VERSION ""

NS_ :

BS_:

BU_: BCM Vector__XX
VAL_TABLE_ MUWenabled 2 "MUW Master and Slave enabled" 1 "MUW Master only enabled" 0 "MUW not enabled" ;
VAL_TABLE_ VoltageState 2 "Critical Under Voltage State" 1 "Under Voltage State" 0 "Normal Voltage State" ;
VAL_TABLE_ Active 1 "Active" 0 "Not Active" ;
VAL_TABLE_ Open 1 "Open" 0 "Closed" ;
VAL_TABLE_ Fail 1 "Fail present" 0 "Fail not present" ;
VAL_TABLE_ Valid 1 "Not Valid" 0 "Valid" ;
VAL_TABLE_ ClutchPedalValidData 1 "Not Valid" 0 "Valid" ;
VAL_TABLE_ ClutchPedalAction 1 "Active" 0 "Not Active" ;
VAL_TABLE_ WakeUpReasons 58 "RB_LPMS_WKPR_NONE" 57 "RB_LPMS_WKPR_LPMS_FAILED" 56 "RB_LPMS_WKPR_MAX" 55 "RB_LPMS_WKPR_MUW_INCLINATION" 54 "RB_LPMS_WKPR_MUW_VOLUMETRIC" 53 "RB_LPMS_WKPR_LIN2_RX_NACK_ERR" 52 "RB_LPMS_WKPR_LIN2_RX_NAP_ERR" 51 "RB_LPMS_WKPR_LIN2_TX_ERR" 50 "RB_LPMS_WKPR_S_TASTER4" 49 "RB_LPMS_WKPR_S_TASTER3" 48 "RB_LPMS_WKPR_S_TASTER2" 47 "RB_LPMS_WKPR_S_TASTER1" 46 "RB_LPMS_WKPR_TAG_R" 45 "RB_LPMS_WKPR_TAG_L" 44 "RB_LPMS_WKPR_KL30G_FB" 43 "RB_LPMS_WKPR_LDS_RED" 42 "RB_LPMS_WKPR_IRUE_NGS_AUS" 41 "RB_LPMS_WKPR_HS_RASTE" 40 "RB_LPMS_WKPR_V_HR" 39 "RB_LPMS_WKPR_V_HL" 38 "RB_LPMS_WKPR_T_HDF" 37 "RB_LPMS_WKPR_SZ_HK" 36 "RB_LPMS_WKPR_LDS_ABL" 35 "RB_LPMS_WKPR_HK_HR" 34 "RB_LPMS_WKPR_HK_VR" 33 "RB_LPMS_WKPR_MOT_HAUBE2" 32 "RB_LPMS_WKPR_MOT_HAUBE1" 31 "RB_LPMS_WKPR_D_HR" 30 "RB_LPMS_WKPR_D_HL" 29 "RB_LPMS_WKPR_S_SOFTTOUCH" 28 "RB_LPMS_WKPR_L_U_TASTE" 27 "RB_LPMS_WKPR_LDS_SL" 26 "RB_LPMS_WKPR_S_WARNBLK" 25 "RB_LPMS_WKPR_KL15_ZAT2" 24 "RB_LPMS_WKPR_KL15_ZAT1" 23 "RB_LPMS_WKPR_KL15_ZAS2" 22 "RB_LPMS_WKPR_KL15_ZAS1" 21 "RB_LPMS_WKPR_KL_S_ZAS" 20 "RB_LPMS_WKPR_LIN14" 19 "RB_LPMS_WKPR_LIN13" 18 "RB_LPMS_WKPR_LIN12" 17 "RB_LPMS_WKPR_LIN11" 16 "RB_LPMS_WKPR_LIN10" 15 "RB_LPMS_WKPR_LIN9" 14 "RB_LPMS_WKPR_LIN8" 13 "RB_LPMS_WKPR_LIN7" 12 "RB_LPMS_WKPR_LIN6" 11 "RB_LPMS_WKPR_LIN5" 10 "RB_LPMS_WKPR_LIN4" 9 "RB_LPMS_WKPR_LIN3" 8 "RB_LPMS_WKPR_LIN2_SOUNDER_ALARM" 7 "RB_LPMS_WKPR_LIN2" 6 "RB_LPMS_WKPR_LIN1" 5 "RB_LPMS_WKPR_CAN3" 4 "RB_LPMS_WKPR_CAN2" 3 "RB_LPMS_WKPR_CAN1" 2 "RB_LPMS_WKPR_KESSY" 1 "RB_LPMS_WKPR_RF" 0 "RB_LPMS_WKPR_PWRON" ;
VAL_TABLE_ ResetReasons 255 "RB_LPMS__RESET_INIT" 254 "RB_LPMS__UNKNOWN_RESET" 47 "RB_LPMS_MST_ERROR_MBIST" 46 "RB_LPMS_MST_ERROR_UNDER_VOLTAGE" 45 "RB_LPMS_MST_ERROR_OVER_VOLTAGE" 44 "RB_LPMS_MST_ERROR_MONDMA" 43 "RB_LPMS_MST_ERROR_XBAR" 42 "RB_LPMS_MST_ERROR_REG_PROTECTION" 41 "RB_LPMS_MST_ERROR_BTST" 40 "RB_LPMS_MST_ERROR_CST" 39 "RB_LPMS_MST_ERROR_PFC" 38 "RB_LPMS_MST_ERROR_CRC" 37 "RB_LPMS_MST_ERROR_TESTMODE" 36 "RB_LPMS_MST_ERROR_STCU" 35 "RB_LPMS_MST_ERROR_DCF" 34 "RB_LPMS_KOT_BUS_ELAPSED" 33 "RB_LPMS_KOT_ECU_ELAPSED" 32 "RB_LPMS_SBC_LEAVING_FSP_MODE" 31 "RB_LPMS_SBC_ILLEGAL_SLEEP_MODE_COMMAND" 30 "RB_LPMS_SBC_V1_OUTPUT_VOLTAGE_ERROR" 29 "RB_LPMS_SBC_LEAVING_OVERLOAD_MODE" 28 "RB_LPMS_SBC_UC_SELF_RESET" 27 "RB_LPMS_SBC_WATCHDOG_ILLEGAL" 26 "RB_LPMS_SBC_WATCHDOG_OVERFLOW" 25 "RB_LPMS_SBC_WATCHDOG_EARLY" 24 "RB_LPMS_SBC_SLEEP_WATCHDOG_OVERFLOW" 23 "RB_LPMS_SBC_POWER_ON_RESET" 22 "RB_LPMS_FES_STDBY_VOLTAGE_ERROR" 21 "RB_LPMS_FES_VOLTAGE_ERROR" 20 "RB_LPMS_FES_TEMPERATURE_ERROR" 19 "RB_LPMS_FES_HSM_RESET" 18 "RB_LPMS_FES_JTAG_OR_STANDBY_EXIT" 17 "RB_LPMS_FES_FCCU_SOFT" 16 "RB_LPMS_FES_FCCU_HARD" 15 "RB_LPMS_FES_SW_RESET" 14 "RB_LPMS_FES_SELF_TEST_COMPLETED" 13 "RB_LPMS_FES_ESR1" 12 "RB_LPMS_DES_STDBY_VOLTAGE_ERROR" 11 "RB_LPMS_DES_VOLTAGE_ERROR" 10 "RB_LPMS_DES_TEMPERATURE_ERROR" 9 "RB_LPMS_DES_HSM_RESET" 8 "RB_LPMS_DES_HW_SSCM" 7 "RB_LPMS_DES_JTAG_RESET" 6 "RB_LPMS_DES_FLASH_FAILURE" 5 "RB_LPMS_DES_FUNCTIONAL" 4 "RB_LPMS_DES_HW_STCU" 3 "RB_LPMS_DES_HW_FCCU" 2 "RB_LPMS_DES_SW_RESET" 1 "RB_LPMS_DES_EXT_POR" 0 "RB_LPMS_MCU_POWER_ON_RESET" ;
VAL_TABLE_ ResetReason_Types 2 "RB_LPMS_MC_RGM_WAKEUP" 1 "RB_LPMS_MC_RGM_OTHER_RESET" 0 "RB_LPMS_MC_RGM_PWON_RESET" ;

BO_ 2665393424 DEBUG_10_SWInfo: 8 BCM
 SG_ DBG10_SwCounter : 39|32@0+ (10,0) [0|0] "ms" Vector__XXX
 SG_ DBG10_SWVersion : 7|32@0+ (1,0) [0|0] "" Vector__XXX

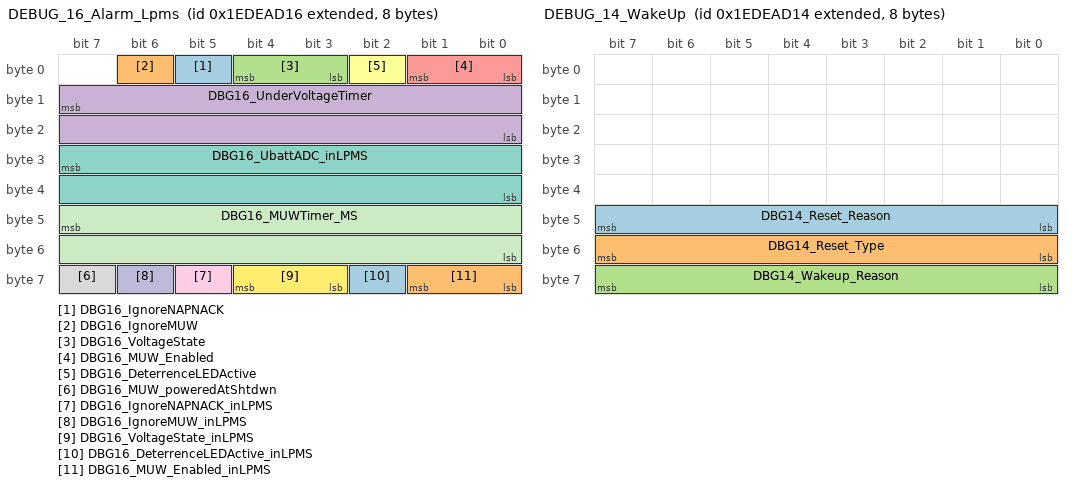
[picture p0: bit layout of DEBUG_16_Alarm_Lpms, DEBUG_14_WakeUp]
BO_ 2665393430 DEBUG_16_Alarm_Lpms: 8 BCM
 SG_ DBG16_IgnoreNAPNACK : 5|1@1+ (1,0) [0|0] "" Vector__XXX
 SG_ DBG16_IgnoreMUW : 6|1@1+ (1,0) [0|0] "" Vector__XXX
 SG_ DBG16_VoltageState : 3|2@1+ (1,0) [0|0] "" Vector__XXX
 SG_ DBG16_UnderVoltageTimer : 15|16@0+ (1,0) [0|0] "ms" Vector__XXX
 SG_ DBG16_MUW_Enabled : 0|2@1+ (1,0) [0|0] "" Vector__XXX
 SG_ DBG16_DeterrenceLEDActive : 2|1@1+ (1,0) [0|0] "" Vector__XXX
 SG_ DBG16_UbattADC_inLPMS : 31|16@0+ (0.000288600288600289,0) [0|18.9134199134199] "Volt" Vector__XXX
 SG_ DBG16_MUW_poweredAtShtdwn : 63|1@1+ (1,0) [0|0] "" Vector__XXX
 SG_ DBG16_IgnoreNAPNACK_inLPMS : 61|1@1+ (1,0) [0|0] "" Vector__XXX
 SG_ DBG16_IgnoreMUW_inLPMS : 62|1@1+ (1,0) [0|0] "" Vector__XXX
 SG_ DBG16_MUWTimer_MS : 47|16@0+ (1,0) [0|0] "ms" Vector__XXX
 SG_ DBG16_VoltageState_inLPMS : 59|2@1+ (1,0) [0|0] "" Vector__XXX
 SG_ DBG16_DeterrenceLEDActive_inLPMS : 58|1@1+ (1,0) [0|0] "" Vector__XXX
 SG_ DBG16_MUW_Enabled_inLPMS : 56|2@1+ (1,0) [0|0] "" Vector__XXX

BO_ 2665393428 DEBUG_14_WakeUp: 8 BCM
 SG_ DBG14_Reset_Reason : 40|8@1+ (1,0) [0|0] "" Vector__XXX
 SG_ DBG14_Reset_Type : 48|8@1+ (1,0) [0|0] "" Vector__XXX
 SG_ DBG14_Wakeup_Reason : 56|8@1+ (1,0) [0|0] "" Vector__XXX

BO_ 2665393429 DEBUG_15_Alarm_VF087: 8 BCM
 SG_ DBG15_PassengerPresence : 3|1@1+ (1,0) [0|1] "" Vector__XXX
 SG_ DBG15_DriverPresence : 2|1@1+ (1,0) [0|1] "" Vector__XXX
 SG_ DBG15_WAl_Activation : 1|1@1+ (1,0) [0|1] "" Vector__XXX
 SG_ DBG15_AlarmSupplySC : 0|8@0+ (1,0) [0|255] "" Vector__XXX
 SG_ DBG15_RFTrunk_VPSTrunkUnlckCntrl : 8|1@0+ (1,0) [0|1] "" Vector__XXX
 SG_ DBG15_TrunkExtCntrl : 23|1@0+ (1,0) [0|1] "" Vector__XXX
 SG_ DBG15_VPSBlinkUnlockCntrl : 22|1@0+ (1,0) [0|1] "" Vector__XXX
 SG_ DBG15_VPSBlinkLockCntrl : 21|1@0+ (1,0) [0|1] "" Vector__XXX
 SG_ DBG15_LIN2_ExtWakeup : 20|1@0+ (1,0) [0|1] "" Vector__XXX
 SG_ DBG15_MUWPowerSupply : 29|1@0+ (1,0) [0|1] "" Vector__XXX
 SG_ DBG15_SelfArmingCntrl : 28|1@0+ (1,0) [0|1] "" Vector__XXX
 SG_ DBG15_VPSAlarmONCntrl_NoMUW : 25|1@0+ (1,0) [0|1] "" Vector__XXX
 SG_ DBG15_VPSAlarmONCntrl : 24|1@0+ (1,0) [0|1] "" Vector__XXX
 SG_ DBG15_VPSAlarmOFFCntrl_NoMUW : 27|1@0+ (1,0) [0|1] "" Vector__XXX
 SG_ DBG15_VPSAlarmOFFCntrl : 26|1@0+ (1,0) [0|1] "" Vector__XXX
 SG_ DBG15_VPSAlarmModeCntrl : 16|3@0+ (1,0) [0|7] "" Vector__XXX
 SG_ DBG15_VPSAlarmBlinkCntrl : 19|3@0+ (1,0) [0|7] "" Vector__XXX
 SG_ DBG15_Excl_MUWStsNoMUW : 39|1@0+ (1,0) [0|1] "" Vector__XXX
 SG_ DBG15_MUWSignal : 38|1@0+ (1,0) [0|1] "" Vector__XXX
 SG_ DBG15_DeterringLed : 37|1@0+ (1,0) [0|1] "" Vector__XXX
 SG_ DBG15_VPSAlarmIFSts : 36|2@0+ (1,0) [0|1] "" Vector__XXX
 SG_ DBG15_VPSAlarmAntinclSts : 34|2@0+ (1,0) [0|1] "" Vector__XXX
 SG_ DBG15_UMAlarmCauseSts : 45|1@0+ (1,0) [0|1] "" Vector__XXX
 SG_ DBG15_AMAlarmCauseSts : 44|1@0+ (1,0) [0|1] "" Vector__XXX
 SG_ DBG15_BonnetAlarmCauseSts : 43|1@0+ (1,0) [0|1] "" Vector__XXX
 SG_ DBG15_RHatchAlarmCauseSts : 42|1@0+ (1,0) [0|1] "" Vector__XXX
 SG_ DBG15_DoorAlarmCausesSts : 41|1@0+ (1,0) [0|1] "" Vector__XXX
 SG_ DBG15_INTInfoAlarmCausesSts : 40|1@0+ (1,0) [0|1] "" Vector__XXX
 SG_ DBG15_Excl_MUWStsWAL : 51|1@0+ (1,0) [0|1] "" Vector__XXX
 SG_ DBG15_ASUAlarmCauseSts : 32|3@0+ (1,0) [0|7] "" Vector__XXX
 SG_ DBG15_StateOfAlarmSystem : 55|4@0+ (1,0) [0|15] "" Vector__XXX
 SG_ DBG15_Excl_PsngrDoorWAL : 50|1@0+ (1,0) [0|1] "" Vector__XXX
 SG_ DBG15_Excl_DriverDoorWAL : 49|1@0+ (1,0) [0|1] "" Vector__XXX
 SG_ DBG15_Excl_UMSts : 63|1@0+ (1,0) [0|1] "" Vector__XXX
 SG_ DBG15_Excl_ASUSts : 48|1@0+ (1,0) [0|1] "" Vector__XXX
 SG_ DBG15_Excl_AMSts : 62|1@0+ (1,0) [0|1] "" Vector__XXX
 SG_ DBG15_SBMT_VpsDoorUnlckCntrl_F08 : 60|1@0+ (1,0) [0|1] "" Vector__XXX
 SG_ DBG15_Excl_TrunkSts : 61|1@0+ (1,0) [0|1] "" Vector__XXX
 SG_ DBG15_SBMT_EnableGlovebox_VF008 : 58|1@0+ (1,0) [0|1] "" Vector__XXX
 SG_ DBG15_SBMT_EnbleDomeLckUnlck_F08 : 59|1@0+ (1,0) [0|1] "" Vector__XXX
 SG_ DBG15_SBMT_EnableDomeLight_VF008 : 57|1@0+ (1,0) [0|1] ""  Vector__XX

CM_ "C1-CAN Network

Created from Signal List file: CommonSignalList_C1-CAN_2021_03_18_Rev449.xls
With Message Map file: F175_MM_C1-CAN_2021_03_18_rev124.xls
for project: F175

Created on: 18/03/2021, 18:02:41
By automated tool: Genera_dbc 4.2.E
Launched by: FERRARI_IP\JMolinari
Ferrari - S.E.E.";
CM_ BU_ BCM "Nodo Body Computer";
BA_DEF_ SG_  "GenSigSendType" ENUM  "NotUsed","OnWrite","OnWriteWithRepetition","OnChange","OnChangeWithRepetition","IfActive","IfActiveWithRepetition","NoSigSendType";
BA_DEF_ BO_  "GenMsgSendType" ENUM  "Cyclic","NotUsed","NotUsed","NotUsed","NotUsed","NotUsed","NotUsed","NotUsed","NoMsgSendType";
BA_DEF_ BO_  "Type" ENUM  "P","C","PE","COC","PE_Cntrl","E","E_Cntrl","OC","S","BAF","DC","EM","MM","-";
BA_DEF_ BU_  "TpOwnSystemEcuNumber" HEX 0 255;
BA_DEF_ BU_  "NwmNodeType" ENUM  "kMaster","kSlave15","kSlave30","none";
BA_DEF_ BU_  "NmNodeType" ENUM  "kMaster","kSlave15","kSlave30","none";
BA_DEF_ BU_  "ILUsed" ENUM  "No","Yes";
BA_DEF_ BU_  "NmNode" ENUM  "No","Yes";
BA_DEF_ BU_  "NmStationAddress" HEX 0 255;
BA_DEF_ BU_  "NodeLayerModules" STRING ;
BA_DEF_ BU_  "Description" STRING ;
BA_DEF_ BU_  "NodeAddress" INT 0 127;
BA_DEF_  "Manufacturer" STRING ;
BA_DEF_  "VersionYear" INT 0 99;
BA_DEF_  "VersionWeek" INT 0 53;
BA_DEF_  "Version" HEX 0 255;
BA_DEF_  "DBName" STRING ;
BA_DEF_  "Baudrate" INT 0 1000000;
BA_DEF_  "NmType" STRING ;
BA_DEF_  "BusType" STRING ;
BA_DEF_DEF_  "GenSigSendType" "NoSigSendType";
BA_DEF_DEF_  "GenMsgSendType" "NoMsgSendType";
BA_DEF_DEF_  "Type" "-";
BA_DEF_DEF_  "TpOwnSystemEcuNumber" 0;
BA_DEF_DEF_  "NwmNodeType" "none";
BA_DEF_DEF_  "NmNodeType" "none";
BA_DEF_DEF_  "ILUsed" "Yes";
BA_DEF_DEF_  "NmNode" "Yes";
BA_DEF_DEF_  "NmStationAddress" 0;
BA_DEF_DEF_  "NodeLayerModules" "Osek_TP.dll";
BA_DEF_DEF_  "Description" "";
BA_DEF_DEF_  "NodeAddress" 0;
BA_DEF_DEF_  "Manufacturer" "Ferrari";
BA_DEF_DEF_  "VersionYear" 13;
BA_DEF_DEF_  "VersionWeek" 51;
BA_DEF_DEF_  "Version" 160;
BA_DEF_DEF_  "DBName" "CAN";
BA_DEF_DEF_  "Baudrate" 500000;
BA_DEF_DEF_  "NmType" "";
BA_DEF_DEF_  "BusType" "";
BA_ "BusType" "CAN";
BA_ "NmType" "Fiat_Class_C";
BA_ "Version" 124;
BA_ "VersionWeek" 11;
BA_ "VersionYear" 21;
BA_ "DBName" "C1CAN";
BA_ "Description" BU_ BCM "Nodo Body Computer";
BA_ "NmNodeType" BU_ BCM 0;
BA_ "NwmNodeType" BU_ BCM 0;
BA_ "TpOwnSystemEcuNumber" BU_ BCM 64;
BA_ "NmStationAddress" BU_ BCM 64;
VAL_ 2665393430 DBG16_VoltageState 2 "Critical Under Voltage State" 1 "Under Voltage State" 0 "Normal Voltage State" ;
VAL_ 2665393430 DBG16_MUW_Enabled 2 "MUW Master and Slave enabled" 1 "MUW Master only enabled" 0 "MUW not enabled" ;
VAL_ 2665393430 DBG16_VoltageState_inLPMS 2 "Critical Under Voltage State" 1 "Under Voltage State" 0 "Normal Voltage State" ;
VAL_ 2665393430 DBG16_MUW_Enabled_inLPMS 2 "MUW Master and Slave enabled" 1 "MUW Master only enabled" 0 "MUW not enabled" ;
VAL_ 2665393428 DBG14_Reset_Reason 255 "RB_LPMS__RESET_INIT" 254 "RB_LPMS__UNKNOWN_RESET" 47 "RB_LPMS_MST_ERROR_MBIST" 46 "RB_LPMS_MST_ERROR_UNDER_VOLTAGE" 45 "RB_LPMS_MST_ERROR_OVER_VOLTAGE" 44 "RB_LPMS_MST_ERROR_MONDMA" 43 "RB_LPMS_MST_ERROR_XBAR" 42 "RB_LPMS_MST_ERROR_REG_PROTECTION" 41 "RB_LPMS_MST_ERROR_BTST" 40 "RB_LPMS_MST_ERROR_CST" 39 "RB_LPMS_MST_ERROR_PFC" 38 "RB_LPMS_MST_ERROR_CRC" 37 "RB_LPMS_MST_ERROR_TESTMODE" 36 "RB_LPMS_MST_ERROR_STCU" 35 "RB_LPMS_MST_ERROR_DCF" 34 "RB_LPMS_KOT_BUS_ELAPSED" 33 "RB_LPMS_KOT_ECU_ELAPSED" 32 "RB_LPMS_SBC_LEAVING_FSP_MODE" 31 "RB_LPMS_SBC_ILLEGAL_SLEEP_MODE_COMMAND" 30 "RB_LPMS_SBC_V1_OUTPUT_VOLTAGE_ERROR" 29 "RB_LPMS_SBC_LEAVING_OVERLOAD_MODE" 28 "RB_LPMS_SBC_UC_SELF_RESET" 27 "RB_LPMS_SBC_WATCHDOG_ILLEGAL" 26 "RB_LPMS_SBC_WATCHDOG_OVERFLOW" 25 "RB_LPMS_SBC_WATCHDOG_EARLY" 24 "RB_LPMS_SBC_SLEEP_WATCHDOG_OVERFLOW" 23 "RB_LPMS_SBC_POWER_ON_RESET" 22 "RB_LPMS_FES_STDBY_VOLTAGE_ERROR" 21 "RB_LPMS_FES_VOLTAGE_ERROR" 20 "RB_LPMS_FES_TEMPERATURE_ERROR" 19 "RB_LPMS_FES_HSM_RESET" 18 "RB_LPMS_FES_JTAG_OR_STANDBY_EXIT" 17 "RB_LPMS_FES_FCCU_SOFT" 16 "RB_LPMS_FES_FCCU_HARD" 15 "RB_LPMS_FES_SW_RESET" 14 "RB_LPMS_FES_SELF_TEST_COMPLETED" 13 "RB_LPMS_FES_ESR1" 12 "RB_LPMS_DES_STDBY_VOLTAGE_ERROR" 11 "RB_LPMS_DES_VOLTAGE_ERROR" 10 "RB_LPMS_DES_TEMPERATURE_ERROR" 9 "RB_LPMS_DES_HSM_RESET" 8 "RB_LPMS_DES_HW_SSCM" 7 "RB_LPMS_DES_JTAG_RESET" 6 "RB_LPMS_DES_FLASH_FAILURE" 5 "RB_LPMS_DES_FUNCTIONAL" 4 "RB_LPMS_DES_HW_STCU" 3 "RB_LPMS_DES_HW_FCCU" 2 "RB_LPMS_DES_SW_RESET" 1 "RB_LPMS_DES_EXT_POR" 0 "RB_LPMS_MCU_POWER_ON_RESET" ;
VAL_ 2665393428 DBG14_Reset_Type 2 "RB_LPMS_MC_RGM_WAKEUP" 1 "RB_LPMS_MC_RGM_OTHER_RESET" 0 "RB_LPMS_MC_RGM_PWON_RESET" ;
VAL_ 2665393428 DBG14_Wakeup_Reason 58 "RB_LPMS_WKPR_NONE" 57 "RB_LPMS_WKPR_LPMS_FAILED" 56 "RB_LPMS_WKPR_MAX" 55 "RB_LPMS_WKPR_MUW_INCLINATION" 54 "RB_LPMS_WKPR_MUW_VOLUMETRIC" 53 "RB_LPMS_WKPR_LIN2_RX_NACK_ERR" 52 "RB_LPMS_WKPR_LIN2_RX_NAP_ERR" 51 "RB_LPMS_WKPR_LIN2_TX_ERR" 50 "RB_LPMS_WKPR_S_TASTER4" 49 "RB_LPMS_WKPR_S_TASTER3" 48 "RB_LPMS_WKPR_S_TASTER2" 47 "RB_LPMS_WKPR_S_TASTER1" 46 "RB_LPMS_WKPR_TAG_R" 45 "RB_LPMS_WKPR_TAG_L" 44 "RB_LPMS_WKPR_KL30G_FB" 43 "RB_LPMS_WKPR_LDS_RED" 42 "RB_LPMS_WKPR_IRUE_NGS_AUS" 41 "RB_LPMS_WKPR_HS_RASTE" 40 "RB_LPMS_WKPR_V_HR" 39 "RB_LPMS_WKPR_V_HL" 38 "RB_LPMS_WKPR_T_HDF" 37 "RB_LPMS_WKPR_SZ_HK" 36 "RB_LPMS_WKPR_LDS_ABL" 35 "RB_LPMS_WKPR_HK_HR" 34 "RB_LPMS_WKPR_HK_VR" 33 "RB_LPMS_WKPR_MOT_HAUBE2" 32 "RB_LPMS_WKPR_MOT_HAUBE1" 31 "RB_LPMS_WKPR_D_HR" 30 "RB_LPMS_WKPR_D_HL" 29 "RB_LPMS_WKPR_S_SOFTTOUCH" 28 "RB_LPMS_WKPR_L_U_TASTE" 27 "RB_LPMS_WKPR_LDS_SL" 26 "RB_LPMS_WKPR_S_WARNBLK" 25 "RB_LPMS_WKPR_KL15_ZAT2" 24 "RB_LPMS_WKPR_KL15_ZAT1" 23 "RB_LPMS_WKPR_KL15_ZAS2" 22 "RB_LPMS_WKPR_KL15_ZAS1" 21 "RB_LPMS_WKPR_KL_S_ZAS" 20 "RB_LPMS_WKPR_LIN14" 19 "RB_LPMS_WKPR_LIN13" 18 "RB_LPMS_WKPR_LIN12" 17 "RB_LPMS_WKPR_LIN11" 16 "RB_LPMS_WKPR_LIN10" 15 "RB_LPMS_WKPR_LIN9" 14 "RB_LPMS_WKPR_LIN8" 13 "RB_LPMS_WKPR_LIN7" 12 "RB_LPMS_WKPR_LIN6" 11 "RB_LPMS_WKPR_LIN5" 10 "RB_LPMS_WKPR_LIN4" 9 "RB_LPMS_WKPR_LIN3" 8 "RB_LPMS_WKPR_LIN2_SOUNDER_ALARM" 7 "RB_LPMS_WKPR_LIN2" 6 "RB_LPMS_WKPR_LIN1" 5 "RB_LPMS_WKPR_CAN3" 4 "RB_LPMS_WKPR_CAN2" 3 "RB_LPMS_WKPR_CAN1" 2 "RB_LPMS_WKPR_KESSY" 1 "RB_LPMS_WKPR_RF" 0 "RB_LPMS_WKPR_PWRON" ;
